# ATmega32M1 register map
Vendor: Atmel; File version: 1.0
CPU: other r0p0, little endian, no MPU, no FPU, 4 interrupt priority bits
Registers are 8-bit, read-write, reset 0x0 unless marked. A register's access mark holds for its fields unless they carry their own. Offsets are from the block's base; [hi:lo] are bit positions; {n}, {i} and the like mark numbered series.

## LOCKBIT — Lockbits
Base 0x00800000
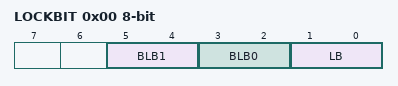
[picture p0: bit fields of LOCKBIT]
0x00 LOCKBIT
  [5:4] BLB1 — Boot Loader Protection Mode
    0=LPM_SPM_DISABLE (LPM and SPM prohibited in Boot Section); 1=LPM_DISABLE (LPM prohibited in Boot Section); 2=SPM_DISABLE (SPM prohibited in Boot Section); 3=NO_LOCK (No lock on SPM and LPM in Boot Section)
  [3:2] BLB0 — Boot Loader Protection Mode
    0=LPM_SPM_DISABLE (LPM and SPM prohibited in Application Section); 1=LPM_DISABLE (LPM prohibited in Application Section); 2=SPM_DISABLE (SPM prohibited in Application Section); 3=NO_LOCK (No lock on SPM and LPM in Application Section)
  [1:0] LB — Memory Lock
    0=PROG_VER_DISABLED (Further programming and verification disabled); 2=PROG_DISABLED (Further programming disabled); 3=NO_LOCK (No memory lock features enabled)

## PORTB — I/O Port
Base 0x00800023
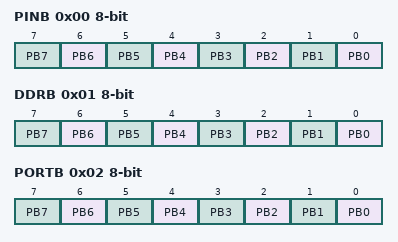
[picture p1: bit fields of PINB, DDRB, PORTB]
0x00 PINB — Port B Input Pins (read-only for debugger)
  [n] PB{n} (n=0..7) — Pin B{n}
0x01 DDRB — Port B Data Direction Register
  [n] PB{n} (n=0..7) — Pin B{n}
0x02 PORTB — Port B Data Register
  [n] PB{n} (n=0..7) — Pin B{n}

## PORTC — I/O Port
Base 0x00800026
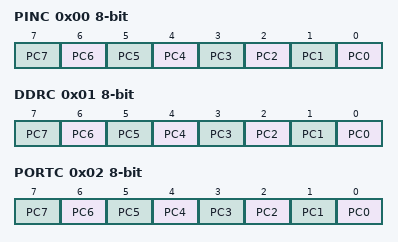
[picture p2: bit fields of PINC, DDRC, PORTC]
0x00 PINC — Port C Input Pins (read-only for debugger)
  [n] PC{n} (n=0..7) — Pin C{n}
0x01 DDRC — Port C Data Direction Register
  [n] PC{n} (n=0..7) — Pin C{n}
0x02 PORTC — Port C Data Register
  [n] PC{n} (n=0..7) — Pin C{n}

## PORTD — I/O Port
Base 0x00800029
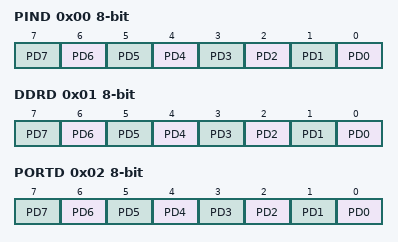
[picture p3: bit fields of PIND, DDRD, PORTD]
0x00 PIND — Port D Input Pins (read-only for debugger)
  [n] PD{n} (n=0..7) — Pin D{n}
0x01 DDRD — Port D Data Direction Register
  [n] PD{n} (n=0..7) — Pin D{n}
0x02 PORTD — Port D Data Register
  [n] PD{n} (n=0..7) — Pin D{n}

## PORTE — I/O Port
Base 0x0080002C
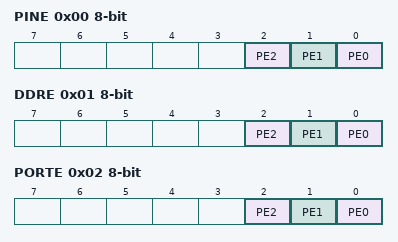
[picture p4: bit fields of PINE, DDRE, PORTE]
0x00 PINE — Port E Input Pins (read-only for debugger)
  [2] PE2 — Pin E2
  [1] PE1 — Pin E1
  [0] PE0 — Pin E0
0x01 DDRE — Port E Data Direction Register
  [2] PE2 — Pin E2
  [1] PE1 — Pin E1
  [0] PE0 — Pin E0
0x02 PORTE — Port E Data Register
  [2] PE2 — Pin E2
  [1] PE1 — Pin E1
  [0] PE0 — Pin E0

## PSC — Power Stage Controller
Base 0x008000A0
0x00 POCR0SA 16-bit (reset mask 0xFF) — PSC Module 0 Output Compare SA Register
{0x2+6i} POCR{i}RA 16-bit (reset mask 0xFF) (i=0..2) — PSC Module {i} Output Compare RA Register
0x04 POCR0SB 16-bit (reset mask 0xFF) — PSC Output Compare SB Register
0x06 POCR1SA 16-bit (reset mask 0xFF) — PSC Output Compare SA Register
0x0A POCR1SB 16-bit (reset mask 0xFF) — PSC Module 1 Output Compare SB Register
0x0C POCR2SA 16-bit (reset mask 0xFF) — PSC Module 2 Output Compare SA Register
0x10 POCR2SB 16-bit (reset mask 0xFF) — PSC Module 2 Output Compare SB Register
0x12 POCR_RB 16-bit (reset mask 0xFF) — PSC Output Compare RB Register
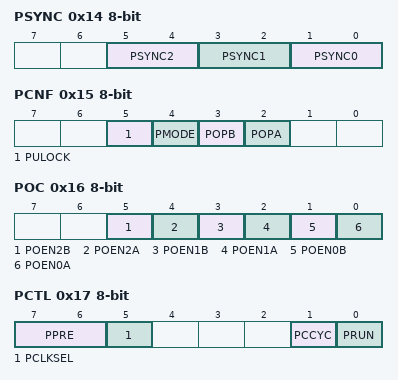
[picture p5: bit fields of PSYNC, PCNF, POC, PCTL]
0x14 PSYNC — PSC Synchro Configuration
  [5:4] PSYNC2 — Selection of Synchronization Out for ADC
  [3:2] PSYNC1 — Selection of Synchronization Out for ADC
  [1:0] PSYNC0 — Selection of Synchronization Out for ADC
0x15 PCNF — PSC Configuration Register
  [5] PULOCK — PSC Update Lock
  [4] PMODE — PSC Mode
  [3] POPB — PSC Output B Polarity
  [2] POPA — PSC Output A Polarity
0x16 POC — PSC Output Configuration
  [5] POEN2B — PSC Output 2B Enable
  [4] POEN2A — PSC Output 2A Enable
  [3] POEN1B — PSC Output 1B Enable
  [2] POEN1A — PSC Output 1A Enable
  [1] POEN0B — PSC Output 0B Enable
  [0] POEN0A — PSC Output 0A Enable
0x17 PCTL — PSC Control Register
  [7:6] PPRE — PSC Prescaler Select bits
  [5] PCLKSEL — PSC Input Clock Select
  [1] PCCYC — PSC Complete Cycle
  [0] PRUN — PSC Run
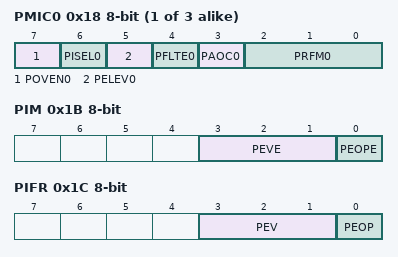
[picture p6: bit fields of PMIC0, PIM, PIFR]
{0x18+i} PMIC{i} (i=0..2) — PSC Module {i} Input Control Register
  [7] POVEN{i} — PSC Module {i} Overlap Enable
  [6] PISEL{i} — PSC Module {i} Input Select
  [5] PELEV{i} — PSC Module {i} Input Level Selector
  [4] PFLTE{i} — PSC Module {i} Input Filter Enable
  [3] PAOC{i} — PSC Module {i} Asynchronous Output Control
  [2:0] PRFM{i} — PSC Module {i} Input Mode bits
0x1B PIM — PSC Interrupt Mask Register
  [3:1] PEVE — External Event 2 Interrupt Enable
  [0] PEOPE — PSC End of Cycle Interrupt Enable
0x1C PIFR — PSC Interrupt Flag Register
  [3:1] PEV — PSC External Event 2 Interrupt
  [0] PEOP — PSC End of Cycle Interrupt
